# STM32H7B3 register map
File version: 3.3
CPU: CM7 r0p1, little endian, MPU, FPU, 4 interrupt priority bits
Registers are 32-bit, read-write, reset 0x0 unless marked. A register's access mark holds for its fields unless they carry their own. Offsets are from the block's base; [hi:lo] are bit positions; {n}, {i} and the like mark numbered series.

## OTG1_HS_PWRCLK — USB 1 on the go high speed
Base 0x40040E00
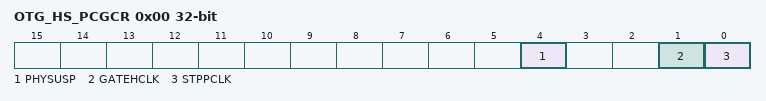
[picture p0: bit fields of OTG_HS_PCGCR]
0x00 OTG_HS_PCGCR — Power and clock gating control register
  [4] PHYSUSP — PHY suspended
  [1] GATEHCLK
  [0] STPPCLK — Stop PHY clock

## OctoSPII_O_Manager
Base 0x5200B400
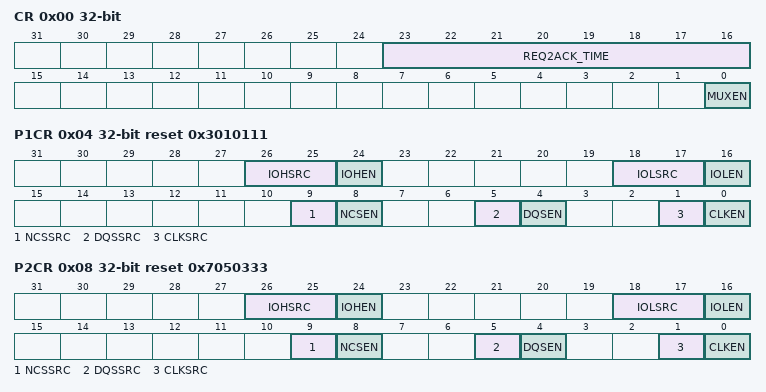
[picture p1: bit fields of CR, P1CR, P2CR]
0x00 CR — OctoSPI IO Manager Control Register
  [23:16] REQ2ACK_TIME — REQ to ACK Time
  [0] MUXEN — Multiplexed mode Enable
0x04 P1CR reset 0x3010111 — OctoSPI IO Manager Port 1 configuration register
  [26:25] IOHSRC
  [24] IOHEN
  [18:17] IOLSRC
  [16] IOLEN
  [9] NCSSRC
  [8] NCSEN
  [5] DQSSRC
  [4] DQSEN
  [1] CLKSRC — CLK/CLKn Source for Port n
  [0] CLKEN — CLK/CLKn Enable for Port n
0x08 P2CR reset 0x7050333 — OctoSPI IO Manager Port 2 configuration register
  [26:25] IOHSRC, [24] IOHEN, [18:17] IOLSRC, [16] IOLEN, [9] NCSSRC, [8] NCSEN, [5] DQSSRC, [4] DQSEN, [1] CLKSRC, [0] CLKEN

## RAMECC — ECC controller is associated to each RAM area
Base 0x52009000
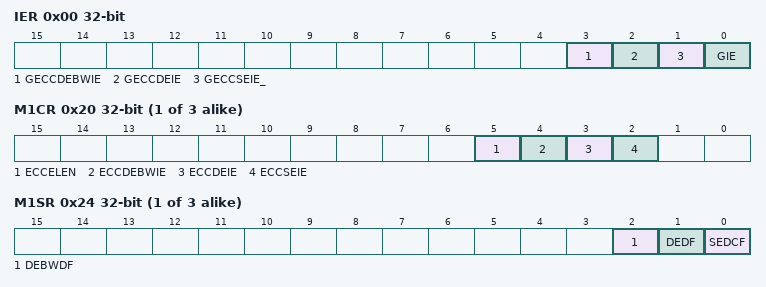
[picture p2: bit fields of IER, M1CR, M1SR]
0x00 IER — RAMECC interrupt enable register
  [3] GECCDEBWIE — Global ECC double error on byte write (BW) interrupt enable
  [2] GECCDEIE — Global ECC double error interrupt enable
  [1] GECCSEIE_ — Global ECC single error interrupt enable
  [0] GIE — Global interrupt enable
{0x0+0x20*i} M{i}CR (i=1..3) — RAMECC monitor x configuration register
  [5] ECCELEN — ECC error latching enable
  [4] ECCDEBWIE — ECC double error on byte write (BW) interrupt enable
  [3] ECCDEIE — ECC double error interrupt enable
  [2] ECCSEIE — ECC single error interrupt enable
{0x4+0x20*i} M{i}SR (i=1..3) — RAMECC monitor x status register
  [2] DEBWDF — ECC double error on byte write (BW) detected flag
  [1] DEDF — ECC double error detected flag
  [0] SEDCF — ECC single error detected and corrected flag
{0x8+0x20*i} M{i}FAR ro (i=1..3) — RAMECC monitor x failing address register
  [31:0] FADD — ECC error failing address
{0xC+0x20*i} M{i}FDRL ro (i=1..3) — RAMECC monitor x failing data low register
  [31:0] FDATAL — Failing data low
0x30 M1FDRH ro — RAMECC monitor x failing data high register
  [31:0] FDATAH — Failing data high (64-bit memory)
0x34 M1FECR — RAMECC monitor x failing ECC error code register
  [31:0] FEC — Failing error code
0x50 M2FDRH — RAMECC monitor x failing data high register
  [31:0] FDATAH — Failing data high (64-bit memory)
0x58 M2FECR — RAMECC monitor x failing ECC error code register
  [31:0] FEC — Failing error code
0x70 M3FDRH ro — RAMECC monitor x failing data high register
  [31:0] FDATAH — Failing data high (64-bit memory)
0x7C M3FECR ro — RAMECC monitor x failing ECC error code register
  [31:0] FEC — Failing error code

## RNG
Base 0x48021800
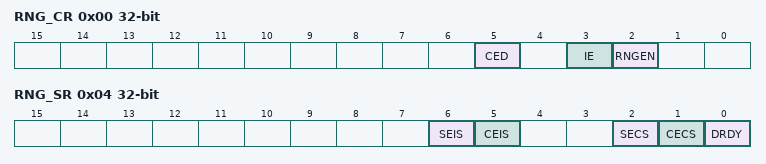
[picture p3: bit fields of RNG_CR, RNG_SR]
0x00 RNG_CR — RNG control register
  [5] CED — Clock error detection Note: The clock error detection can be used only when ck_rc48 or ck_pll1_q (ck_pll1_q = 48MHz) source is selected otherwise, CED bit must be equal to 1. The clock error detection cannot be enabled nor disabled on the fly when RNG peripheral is enabled, to enable or disable CED the RNG must be disabled.
  [3] IE — Interrupt enable
  [2] RNGEN — Random number generator enable
0x04 RNG_SR access per field — RNG status register
  [6] SEIS rw — Seed error interrupt status This bit is set at the same time as SECS. It is cleared by writing it to 0. ** More than 64 consecutive bits at the same value (0 or 1) ** More than 32 consecutive alternances of 0 and 1 (0101010101...01) An interrupt is pending if IE = 1 in the RNG_CR register.
  [5] CEIS rw — Clock error interrupt status This bit is set at the same time as CECS. It is cleared by writing it to 0. An interrupt is pending if IE = 1 in the RNG_CR register. Note: This bit is meaningless if CED (Clock error detection) bit in RNG_CR is equal to 1.
  [2] SECS ro — Seed error current status ** More than 64 consecutive bits at the same value (0 or 1) ** More than 32 consecutive alternances of 0 and 1 (0101010101...01)
  [1] CECS ro — Clock error current status Note: This bit is meaningless if CED (Clock error detection) bit in RNG_CR is equal to 1.
  [0] DRDY ro — Data ready Note: If IE=1 in RNG_CR, an interrupt is generated when DRDY=1. It can rise when the peripheral is disabled. When the output buffer becomes empty (after reading RNG_DR), this bit returns to 0 until a new random value is generated.
0x08 RNG_DR ro — The RNG_DR register is a read-only register that delivers a 32-bit random value when read. The content of this register is valid when DRDY= 1, even if RNGEN=0.
  [31:0] RNDATA — Random data 32-bit random data which are valid when DRDY=1.
